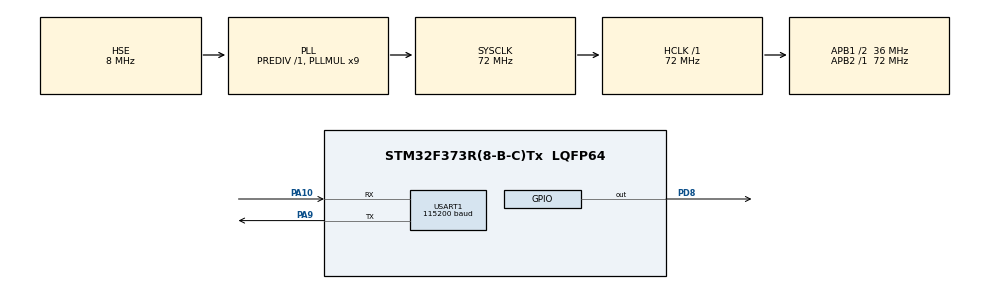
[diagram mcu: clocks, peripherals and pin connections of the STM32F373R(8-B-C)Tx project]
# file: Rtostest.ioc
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Mcu.Family=STM32F3
Mcu.Name=STM32F373R(8-B-C)Tx
Mcu.Package=LQFP64
NVIC.PriorityGroup=NVIC_PRIORITYGROUP_4
NVIC.TIM19_IRQn=true\:15\:0\:false\:false\:true\:false\:true\:true
NVIC.TimeBase=TIM19_IRQn
NVIC.TimeBaseIP=TIM19
PA10.Mode=Asynchronous
PA10.Signal=USART1_RX
PA13.Mode=Serial_Wire
PA13.Signal=SYS_JTMS-SWDIO
PA14.Mode=Serial_Wire
PA14.Signal=SYS_JTCK-SWCLK
PA9.Mode=Asynchronous
PA9.Signal=USART1_TX
PD8.Signal=GPIO_Output
PF0-OSC_IN.Mode=HSE-External-Oscillator
PF0-OSC_IN.Signal=RCC_OSC_IN
PF1-OSC_OUT.Mode=HSE-External-Oscillator
PF1-OSC_OUT.Signal=RCC_OSC_OUT
ProjectManager.HeapSize=0x200
ProjectManager.StackSize=0x400
ProjectManager.TargetToolchain=MDK-ARM V5.32
RCC.AHBFreq_Value=72000000
RCC.APB1CLKDivider=RCC_HCLK_DIV2
RCC.APB1Freq_Value=36000000
RCC.APB1TimFreq_Value=72000000
RCC.APB2Freq_Value=72000000
RCC.APB2TimFreq_Value=72000000
RCC.CortexFreq_Value=72000000
RCC.HCLKFreq_Value=72000000
RCC.HSE_VALUE=8000000
RCC.HSI_VALUE=8000000
RCC.LSE_VALUE=32768
RCC.PLLMUL=RCC_PLL_MUL9
RCC.PLLSourceVirtual=RCC_PLLSOURCE_HSE
RCC.SYSCLKFreq_VALUE=72000000
RCC.SYSCLKSource=RCC_SYSCLKSOURCE_PLLCLK
RCC.USBFreq_Value=72000000
USART1.BaudRate=115200
USART1.DMADisableonRxErrorParam=ADVFEATURE_DMA_DISABLEONRXERROR
USART1.OverrunDisableParam=ADVFEATURE_OVERRUN_DISABLE
USART1.VirtualMode-Asynchronous=VM_ASYNC
VP_SYS_VS_tim19.Mode=TIM19
board=custom

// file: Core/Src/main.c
/* USER CODE BEGIN Header */
/**
  ******************************************************************************
  * @file           : main.c
  * @brief          : Main program body
  ******************************************************************************
  * @attention
  *
  * Copyright (c) 2023 STMicroelectronics.
  * All rights reserved.
  *
  * This software is licensed under terms that can be found in the LICENSE file
  * in the root directory of this software component.
  * If no LICENSE file comes with this software, it is provided AS-IS.
  *
  ******************************************************************************
  */
/* USER CODE END Header */
#include "main.h"
#include "usart.h"
#include "gpio.h"

/* USER CODE BEGIN Includes */
#include "FreeRTOS.h"
#include "task.h"
 /* 创建任务句柄 */
 TaskHandle_t AppTaskCreate_Handle;
 TaskHandle_t AppTaskCreate_Handle_2;

/* USER CODE END Includes */

void SystemClock_Config(void);

/* USER CODE BEGIN 0 */
void AppTaskCreate(void)
{
    while(1)
    {

	myPrint("%d\n",123);
	myPrint("%d(int0)\n", 0);
	myPrint("%d(int100)\n", 100);
	myPrint("int(-123) =%d \n", -123);
	myPrint("%d(int 123)\n", 123);
	myPrint("%d(int 0x1234=4660)\n", 0x1234);
	myPrint("%d(int 0x12345678=305419896)\n", 0x12345678);
	myPrint("oct %o(int 0x1234=011064)\n", 0x1234);
	myPrint("oct %o(int 0x12345678=02215053170)\n", 0x12345678);
	myPrint("hex(0x0)=%x\n", 0x0);
	myPrint("hex(0x100)=%x\n", 0x100);
	myPrint("hex(0x1234)=%x\n", 0x1234);
	myPrint("hex(0x7fffffff)=0x%x\n", 0x7fffffff);
	myPrint("hex(0xffffffff)=0x%x\n", 0xffffffff);
    HAL_Delay(5100);

//       vTaskDelete(AppTaskCreate_Handle); //删除AppTaskCreate任务
//        taskEXIT_CRITICAL();            //退出临界区
    }
}

void AppTaskCreate2(void)
{
    while(1)
    {

	myPrint("str=%s\n", "hello");
	myPrint("%s(str)\n", "hello");
	myPrint("ch =%c\n", 'a');
	myPrint("%c(ch)\n", 'a');
	myPrint("float(3.141592) = %f\n", 3.141592);
	printf("=====pinrf:float= %f\n\r\n", 3.141592);
	myPrint("float(123456789.123456789) = %f\n", 123456789.123456789);
	printf("=========pinrf:float = %f\n\r\n", 123456789.123456789);
	myPrint("float(123456.123456789) = %f\n", 123456.123456789);
	printf("==========pinrf:float = %f\n\r\n", 123456.123456789);
	myPrint("%d %s\n\r\n", 123, "abc");
    HAL_Delay(5000);
//       vTaskDelete(AppTaskCreate_Handle); //删除AppTaskCreate任务
//        taskEXIT_CRITICAL();            //退出临界区
    }
}
/* USER CODE END 0 */

int main(void)
{
  /* USER CODE BEGIN 1 */
  BaseType_t xReturn = pdPASS;/* 定义一个创建信息返回值，默认为pdPASS */

  /* USER CODE END 1 */

  /* MCU Configuration--------------------------------------------------------*/

  /* Reset of all peripherals, Initializes the Flash interface and the Systick. */
  HAL_Init();

  /* Configure the system clock */
  SystemClock_Config();

  /* Initialize all configured peripherals */
  MX_GPIO_Init();
  MX_USART1_UART_Init();
  /* USER CODE BEGIN 2 */

   /* 创建 AppTaskCreate 任务 */
   xReturn = xTaskCreate((TaskFunction_t )AppTaskCreate,  /* 任务入口函数 */
                        (const char*    )"AppTaskCreate",/* 任务名字 */
                        (uint16_t       )512,  /* 任务栈大小 */
                        (void*          )NULL,/* 任务入口函数参数 */
                        (UBaseType_t    )5, /* 任务的优先级 */
                        (TaskHandle_t*  )&AppTaskCreate_Handle);/* 任务控制块指针 */
   xReturn = xTaskCreate((TaskFunction_t )AppTaskCreate2,  /* 任务入口函数 */
                        (const char*    )"AppTaskCreate_2",/* 任务名字 */
                        (uint16_t       )512,  /* 任务栈大小 */
                        (void*          )NULL,/* 任务入口函数参数 */
                        (UBaseType_t    )5, /* 任务的优先级 */
                        (TaskHandle_t*  )&AppTaskCreate_Handle_2);/* 任务控制块指针 */
	if(pdFAIL != xReturn)/* 创建成功 */
    vTaskStartScheduler();/* 启动任务，开启调度 */
  /* USER CODE END 2 */

  /* Infinite loop */
  while (1)
  {

  }
}

void SystemClock_Config(void)
{
  RCC_OscInitTypeDef RCC_OscInitStruct = {0};
  RCC_ClkInitTypeDef RCC_ClkInitStruct = {0};
  RCC_PeriphCLKInitTypeDef PeriphClkInit = {0};

  /** Initializes the RCC Oscillators according to the specified parameters
  * in the RCC_OscInitTypeDef structure.
  */
  RCC_OscInitStruct.OscillatorType = RCC_OSCILLATORTYPE_HSE;
  RCC_OscInitStruct.HSEState = RCC_HSE_ON;
  RCC_OscInitStruct.HSEPredivValue = RCC_HSE_PREDIV_DIV1;
  RCC_OscInitStruct.HSIState = RCC_HSI_ON;
  RCC_OscInitStruct.PLL.PLLState = RCC_PLL_ON;
  RCC_OscInitStruct.PLL.PLLSource = RCC_PLLSOURCE_HSE;
  RCC_OscInitStruct.PLL.PLLMUL = RCC_PLL_MUL9;
  if (HAL_RCC_OscConfig(&RCC_OscInitStruct) != HAL_OK)
  {
    Error_Handler();
  }

  /** Initializes the CPU, AHB and APB buses clocks
  */
  RCC_ClkInitStruct.ClockType = RCC_CLOCKTYPE_HCLK|RCC_CLOCKTYPE_SYSCLK
                              |RCC_CLOCKTYPE_PCLK1|RCC_CLOCKTYPE_PCLK2;
  RCC_ClkInitStruct.SYSCLKSource = RCC_SYSCLKSOURCE_PLLCLK;
  RCC_ClkInitStruct.AHBCLKDivider = RCC_SYSCLK_DIV1;
  RCC_ClkInitStruct.APB1CLKDivider = RCC_HCLK_DIV2;
  RCC_ClkInitStruct.APB2CLKDivider = RCC_HCLK_DIV1;

  if (HAL_RCC_ClockConfig(&RCC_ClkInitStruct, FLASH_LATENCY_2) != HAL_OK)
  {
    Error_Handler();
  }
  PeriphClkInit.PeriphClockSelection = RCC_PERIPHCLK_USART1;
  PeriphClkInit.Usart1ClockSelection = RCC_USART1CLKSOURCE_PCLK2;
  if (HAL_RCCEx_PeriphCLKConfig(&PeriphClkInit) != HAL_OK)
  {
    Error_Handler();
  }
}

void HAL_TIM_PeriodElapsedCallback(TIM_HandleTypeDef *htim)
{
  if (htim->Instance == TIM19) {
    HAL_IncTick();
  }
}

void Error_Handler(void)
{
  __disable_irq();
  while (1)
  {
  }
}
